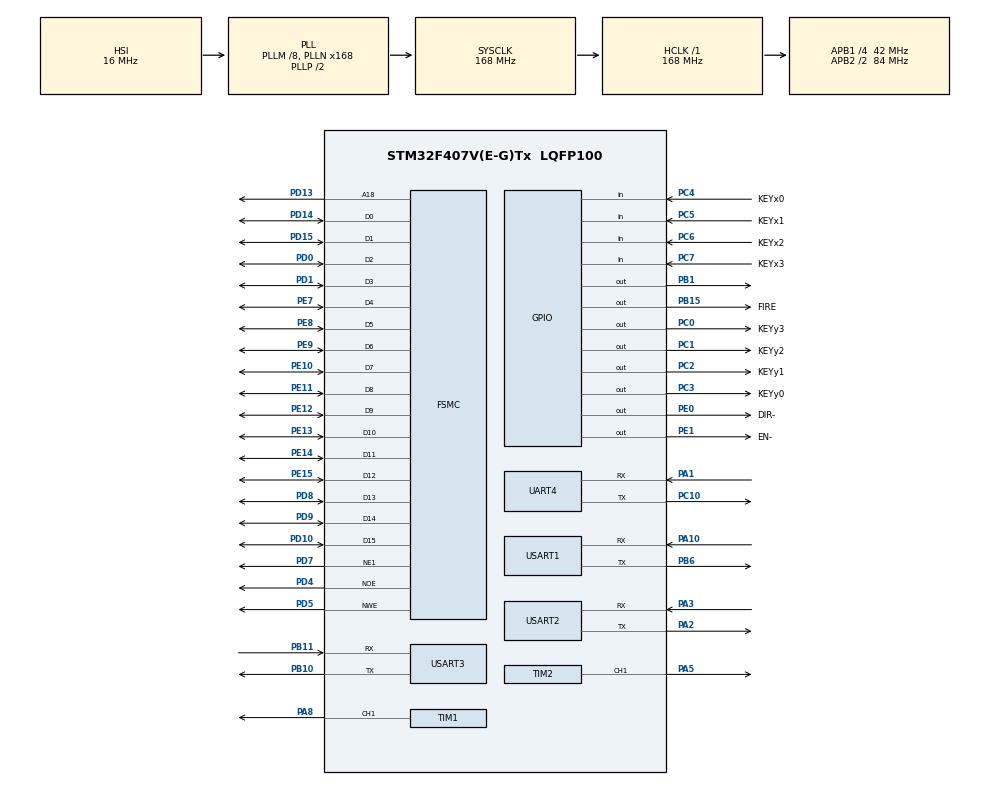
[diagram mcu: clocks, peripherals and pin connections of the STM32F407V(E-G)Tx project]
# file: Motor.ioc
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FSMC.BusTurnAroundDuration1=0
FSMC.DataSetupTime1=24
FSMC.ExtendedAddressSetupTime1=3
FSMC.ExtendedBusTurnAroundDuration1=0
FSMC.ExtendedDataSetupTime1=2
FSMC.ExtendedMode1=FSMC_EXTENDED_MODE_ENABLE
Mcu.Family=STM32F4
Mcu.Name=STM32F407V(E-G)Tx
Mcu.Package=LQFP100
NVIC.PriorityGroup=NVIC_PRIORITYGROUP_4
NVIC.TIM2_IRQn=true\:0\:0\:false\:false\:true\:true\:true
NVIC.USART1_IRQn=true\:1\:0\:true\:false\:true\:true\:true
NVIC.USART2_IRQn=true\:2\:0\:true\:false\:true\:true\:true
NVIC.USART3_IRQn=true\:3\:0\:true\:false\:true\:true\:true
PA0-WKUP.Mode=SYS_WakeUp0
PA0-WKUP.Signal=SYS_WKUP
PA1.Mode=Asynchronous
PA1.Signal=UART4_RX
PA10.Mode=Asynchronous
PA10.Signal=USART1_RX
PA13.Mode=Serial_Wire
PA13.Signal=SYS_JTMS-SWDIO
PA14.Mode=Serial_Wire
PA14.Signal=SYS_JTCK-SWCLK
PA2.Mode=Asynchronous
PA2.Signal=USART2_TX
PA3.Mode=Asynchronous
PA3.Signal=USART2_RX
PA5.Signal=S_TIM2_CH1_ETR
PA8.Signal=S_TIM1_CH1
PB1.Signal=GPIO_Output
PB10.Mode=Asynchronous
PB10.Signal=USART3_TX
PB11.Mode=Asynchronous
PB11.Signal=USART3_RX
PB15.GPIO_Label=FIRE
PB15.PinState=GPIO_PIN_SET
PB15.Signal=GPIO_Output
PB6.Mode=Asynchronous
PB6.Signal=USART1_TX
PC0.GPIO_Label=KEYy3
PC0.GPIO_ModeDefaultOutputPP=GPIO_MODE_OUTPUT_PP
PC0.Signal=GPIO_Output
PC1.GPIO_Label=KEYy2
PC1.GPIO_ModeDefaultOutputPP=GPIO_MODE_OUTPUT_PP
PC1.Signal=GPIO_Output
PC10.Mode=Asynchronous
PC10.Signal=UART4_TX
PC14-OSC32_IN.Mode=LSE-External-Oscillator
PC14-OSC32_IN.Signal=RCC_OSC32_IN
PC15-OSC32_OUT.Mode=LSE-External-Oscillator
PC15-OSC32_OUT.Signal=RCC_OSC32_OUT
PC2.GPIO_Label=KEYy1
PC2.GPIO_ModeDefaultOutputPP=GPIO_MODE_OUTPUT_PP
PC2.Signal=GPIO_Output
PC3.GPIO_Label=KEYy0
PC3.GPIO_ModeDefaultOutputPP=GPIO_MODE_OUTPUT_PP
PC3.Signal=GPIO_Output
PC4.GPIO_Label=KEYx0
PC4.GPIO_PuPd=GPIO_PULLUP
PC4.Signal=GPIO_Input
PC5.GPIO_Label=KEYx1
PC5.GPIO_PuPd=GPIO_PULLUP
PC5.Signal=GPIO_Input
PC6.GPIO_Label=KEYx2
PC6.GPIO_PuPd=GPIO_PULLUP
PC6.Signal=GPIO_Input
PC7.GPIO_Label=KEYx3
PC7.GPIO_PuPd=GPIO_PULLUP
PC7.Signal=GPIO_Input
PD0.Mode=16b-d1
PD0.Signal=FSMC_D2
PD1.Mode=16b-d1
PD1.Signal=FSMC_D3
PD10.Mode=16b-d1
PD10.Signal=FSMC_D15
PD13.Mode=A18_1
PD13.Signal=FSMC_A18
PD14.Mode=16b-d1
PD14.Signal=FSMC_D0
PD15.Mode=16b-d1
PD15.Signal=FSMC_D1
PD4.Mode=Lcd1
PD4.Signal=FSMC_NOE
PD5.Mode=Lcd1
PD5.Signal=FSMC_NWE
PD7.Mode=NorPsramChipSelect1_1
PD7.Signal=FSMC_NE1
PD8.Mode=16b-d1
PD8.Signal=FSMC_D13
PD9.Mode=16b-d1
PD9.Signal=FSMC_D14
PE0.GPIO_Label=DIR-
PE0.GPIO_Speed=GPIO_SPEED_FREQ_VERY_HIGH
PE0.PinState=GPIO_PIN_SET
PE0.Signal=GPIO_Output
PE1.GPIO_Label=EN-
PE1.GPIO_Speed=GPIO_SPEED_FREQ_VERY_HIGH
PE1.PinState=GPIO_PIN_RESET
PE1.Signal=GPIO_Output
PE10.Mode=16b-d1
PE10.Signal=FSMC_D7
PE11.Mode=16b-d1
PE11.Signal=FSMC_D8
PE12.Mode=16b-d1
PE12.Signal=FSMC_D9
PE13.Mode=16b-d1
PE13.Signal=FSMC_D10
PE14.Mode=16b-d1
PE14.Signal=FSMC_D11
PE15.Mode=16b-d1
PE15.Signal=FSMC_D12
PE7.Mode=16b-d1
PE7.Signal=FSMC_D4
PE8.Mode=16b-d1
PE8.Signal=FSMC_D5
PE9.Mode=16b-d1
PE9.Signal=FSMC_D6
PH0-OSC_IN.Mode=HSE-External-Oscillator
PH0-OSC_IN.Signal=RCC_OSC_IN
PH1-OSC_OUT.Mode=HSE-External-Oscillator
PH1-OSC_OUT.Signal=RCC_OSC_OUT
ProjectManager.HeapSize=0x200
ProjectManager.StackSize=0x400
ProjectManager.TargetToolchain=MDK-ARM V5
RCC.48MHZClocksFreq_Value=84000000
RCC.AHBFreq_Value=168000000
RCC.APB1CLKDivider=RCC_HCLK_DIV4
RCC.APB1Freq_Value=42000000
RCC.APB1TimFreq_Value=84000000
RCC.APB2CLKDivider=RCC_HCLK_DIV2
RCC.APB2Freq_Value=84000000
RCC.APB2TimFreq_Value=168000000
RCC.CortexFreq_Value=168000000
RCC.HCLKFreq_Value=168000000
RCC.HSE_VALUE=25000000
RCC.HSI_VALUE=16000000
RCC.PLLM=8
RCC.PLLN=168
RCC.SYSCLKFreq_VALUE=168000000
RCC.SYSCLKSource=RCC_SYSCLKSOURCE_PLLCLK
RCC.VCOOutputFreq_Value=336000000
SH.S_TIM1_CH1.0=TIM1_CH1,PWM Generation1 CH1
SH.S_TIM2_CH1_ETR.0=TIM2_CH1,PWM Generation1 CH1
TIM1.Channel-PWM\ Generation1\ CH1=TIM_CHANNEL_1
TIM1.Period=39999
TIM1.Prescaler=83
TIM2.Channel-PWM\ Generation1\ CH1=TIM_CHANNEL_1
TIM2.Period=999
TIM2.Prescaler=83
TIM2.Pulse-PWM\ Generation1\ CH1=0
TIM5.Period=65535
TIM5.Prescaler=83
UART4.VirtualMode=Asynchronous
USART1.VirtualMode=VM_ASYNC
USART2.VirtualMode=VM_ASYNC
USART3.VirtualMode=VM_ASYNC
VP_TIM1_VS_ClockSourceINT.Mode=Internal
VP_TIM2_VS_ClockSourceINT.Mode=Internal
VP_TIM5_VS_ClockSourceINT.Mode=Internal
board=custom

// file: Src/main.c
/* USER CODE BEGIN Header */
/**
  ******************************************************************************
  * @file           : main.c
  * @brief          : Main program body
  ******************************************************************************
  * @attention
  *
  * <h2><center>&copy; Copyright (c) 2019 STMicroelectronics.
  * All rights reserved.</center></h2>
  *
  * This software component is licensed by ST under BSD 3-Clause license,
  * the "License"; You may not use this file except in compliance with the
  * License. You may obtain a copy of the License at:
  *                        opensource.org/licenses/BSD-3-Clause
  *
  ******************************************************************************
  */
/* USER CODE END Header */

#include "main.h"
#include "tim.h"
#include "usart.h"
#include "gpio.h"
#include "fsmc.h"

/* USER CODE BEGIN Includes */
#include "UserMain.h"
/* USER CODE END Includes */

void SystemClock_Config(void);

int main(void)
{

  /* MCU Configuration--------------------------------------------------------*/

  /* Reset of all peripherals, Initializes the Flash interface and the Systick. */
  HAL_Init();

  /* Configure the system clock */
  SystemClock_Config();

  /* Initialize all configured peripherals */
  MX_GPIO_Init();
  MX_TIM2_Init();
  MX_FSMC_Init();
  MX_TIM5_Init();
  MX_USART1_UART_Init();
  MX_USART2_UART_Init();
  MX_USART3_UART_Init();
  MX_TIM1_Init();
  MX_UART4_Init();

  /* Infinite loop */
  while (1)
  {

    /* USER CODE BEGIN 3 */
		User_Main();
  }
  /* USER CODE END 3 */
}

void SystemClock_Config(void)
{
  RCC_OscInitTypeDef RCC_OscInitStruct = {0};
  RCC_ClkInitTypeDef RCC_ClkInitStruct = {0};

  /** Configure the main internal regulator output voltage
  */
  __HAL_RCC_PWR_CLK_ENABLE();
  __HAL_PWR_VOLTAGESCALING_CONFIG(PWR_REGULATOR_VOLTAGE_SCALE1);
  /** Initializes the CPU, AHB and APB busses clocks
  */
  RCC_OscInitStruct.OscillatorType = RCC_OSCILLATORTYPE_HSI;
  RCC_OscInitStruct.HSIState = RCC_HSI_ON;
  RCC_OscInitStruct.HSICalibrationValue = RCC_HSICALIBRATION_DEFAULT;
  RCC_OscInitStruct.PLL.PLLState = RCC_PLL_ON;
  RCC_OscInitStruct.PLL.PLLSource = RCC_PLLSOURCE_HSI;
  RCC_OscInitStruct.PLL.PLLM = 8;
  RCC_OscInitStruct.PLL.PLLN = 168;
  RCC_OscInitStruct.PLL.PLLP = RCC_PLLP_DIV2;
  RCC_OscInitStruct.PLL.PLLQ = 4;
  if (HAL_RCC_OscConfig(&RCC_OscInitStruct) != HAL_OK)
  {
    Error_Handler();
  }
  /** Initializes the CPU, AHB and APB busses clocks
  */
  RCC_ClkInitStruct.ClockType = RCC_CLOCKTYPE_HCLK|RCC_CLOCKTYPE_SYSCLK
                              |RCC_CLOCKTYPE_PCLK1|RCC_CLOCKTYPE_PCLK2;
  RCC_ClkInitStruct.SYSCLKSource = RCC_SYSCLKSOURCE_PLLCLK;
  RCC_ClkInitStruct.AHBCLKDivider = RCC_SYSCLK_DIV1;
  RCC_ClkInitStruct.APB1CLKDivider = RCC_HCLK_DIV4;
  RCC_ClkInitStruct.APB2CLKDivider = RCC_HCLK_DIV2;

  if (HAL_RCC_ClockConfig(&RCC_ClkInitStruct, FLASH_LATENCY_5) != HAL_OK)
  {
    Error_Handler();
  }
}

void Error_Handler(void)
{
}

/************************ (C) COPYRIGHT STMicroelectronics *****END OF FILE****/
